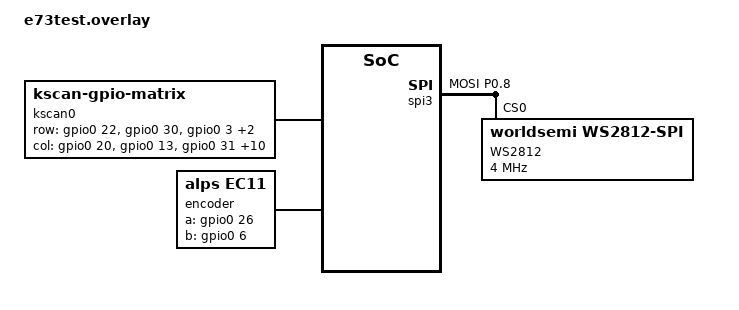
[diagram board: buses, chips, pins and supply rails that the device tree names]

#include <dt-bindings/led/led.h>

#include <dt-bindings/zmk/matrix_transform.h>
/ {
    chosen {
        zmk,kscan = &kscan0;
        zmk,underglow = &led_strip;
	};


	kscan0: kscan_0  {
        	compatible = "zmk,kscan-gpio-matrix";
        	wakeup-source;

        	diode-direction = "col2row";

        	row-gpios
            	= <&gpio0 22 (GPIO_ACTIVE_HIGH | GPIO_PULL_DOWN)>
            	, <&gpio0 30 (GPIO_ACTIVE_HIGH | GPIO_PULL_DOWN)>
	    	, <&gpio0 3 (GPIO_ACTIVE_HIGH | GPIO_PULL_DOWN)>
            	, <&gpio1 6 (GPIO_ACTIVE_HIGH | GPIO_PULL_DOWN)>
            	, <&gpio0 10 (GPIO_ACTIVE_HIGH | GPIO_PULL_DOWN)>

            	;  
        	col-gpios
            	= <&gpio0 20 GPIO_ACTIVE_HIGH>
            	, <&gpio0 13 GPIO_ACTIVE_HIGH>
            	, <&gpio0 31 GPIO_ACTIVE_HIGH>
            	, <&gpio0 24 GPIO_ACTIVE_HIGH>
            	, <&gpio0 29 GPIO_ACTIVE_HIGH>
            	, <&gpio1 0 GPIO_ACTIVE_HIGH>
            	, <&gpio0 2 GPIO_ACTIVE_HIGH>
            	, <&gpio1 2 GPIO_ACTIVE_HIGH>
            	, <&gpio1 13 GPIO_ACTIVE_HIGH>
            	, <&gpio1 4 GPIO_ACTIVE_HIGH>
		, <&gpio0 28 GPIO_ACTIVE_HIGH>
		, <&gpio0 9 GPIO_ACTIVE_HIGH>
		, <&gpio1 11 GPIO_ACTIVE_HIGH>
            	;
    	};

	

	encoder: encoder {
        	compatible = "alps,ec11";
        	a-gpios = <&gpio0 26 (GPIO_ACTIVE_HIGH | GPIO_PULL_UP)>;
        	b-gpios = <&gpio0 6 (GPIO_ACTIVE_HIGH | GPIO_PULL_UP)>;
        	steps = <80>;
        	status = "okay";
    	};

    	sensors: sensors {
        	compatible = "zmk,keymap-sensors";
        	sensors = <&encoder>;
        	triggers-per-rotation = <20>;
    	};
};

&pinctrl {
    spi3_default: spi3_default {
        group1 {
            psels = <NRF_PSEL(SPIM_MOSI, 0, 8)>;
        };
    };

    spi3_sleep: spi3_sleep {
        group1 {
            psels = <NRF_PSEL(SPIM_MOSI, 0, 8)>;
            low-power-enable;
        };
    };
};

&spi3 {
    compatible = "nordic,nrf-spim";
    status = "okay";

    pinctrl-0 = <&spi3_default>;
    pinctrl-1 = <&spi3_sleep>;
    pinctrl-names = "default", "sleep";

    led_strip: ws2812@0 {
        compatible = "worldsemi,ws2812-spi";
        label = "WS2812";

        /* SPI */
        reg = <0>; /* ignored, but necessary for SPI bindings */
        spi-max-frequency = <4000000>;

        /* WS2812 */
        chain-length = <2>; /* arbitrary; change at will */
        spi-one-frame = <0x70>;
        spi-zero-frame = <0x40>;
        color-mapping = <LED_COLOR_ID_GREEN LED_COLOR_ID_RED LED_COLOR_ID_BLUE>;
    };
};
